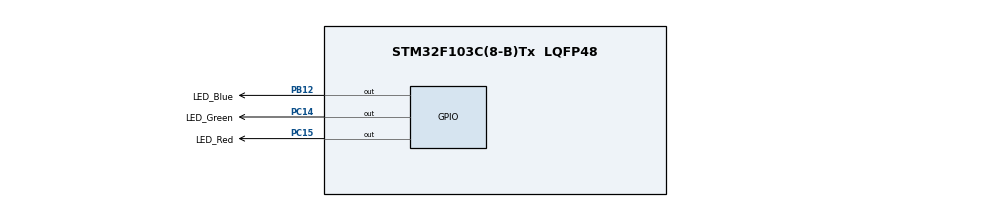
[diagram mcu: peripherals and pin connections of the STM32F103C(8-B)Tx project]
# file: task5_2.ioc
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FREERTOS.Tasks01=defaultTask,0,128,StartDefaultTask,Default,NULL,Dynamic,NULL,NULL;GreenLedTask,-1,128,StartGreenLedTask,Default,NULL,Dynamic,NULL,NULL;RedLedTask,0,128,StartRedLedTask,Default,NULL,Dynamic,NULL,NULL
Mcu.Family=STM32F1
Mcu.Name=STM32F103C(8-B)Tx
Mcu.Package=LQFP48
NVIC.PriorityGroup=NVIC_PRIORITYGROUP_4
NVIC.TIM2_IRQn=true\:15\:0\:false\:false\:true\:false\:false\:true\:true
NVIC.TimeBase=TIM2_IRQn
NVIC.TimeBaseIP=TIM2
PA13.Mode=Serial_Wire
PA13.Signal=SYS_JTMS-SWDIO
PA14.Mode=Serial_Wire
PA14.Signal=SYS_JTCK-SWCLK
PB12.GPIO_Label=LED_Blue
PB12.Signal=GPIO_Output
PC14-OSC32_IN.GPIO_Label=LED_Green
PC14-OSC32_IN.Signal=GPIO_Output
PC15-OSC32_OUT.GPIO_Label=LED_Red
PC15-OSC32_OUT.Signal=GPIO_Output
PD0-OSC_IN.Mode=HSE-External-Oscillator
PD0-OSC_IN.Signal=RCC_OSC_IN
PD1-OSC_OUT.Mode=HSE-External-Oscillator
PD1-OSC_OUT.Signal=RCC_OSC_OUT
ProjectManager.HeapSize=0x200
ProjectManager.StackSize=0x400
ProjectManager.TargetToolchain=STM32CubeIDE
RCC.APB1Freq_Value=8000000
RCC.APB2Freq_Value=8000000
VP_FREERTOS_VS_CMSIS_V1.Mode=CMSIS_V1
VP_SYS_VS_tim2.Mode=TIM2
board=custom

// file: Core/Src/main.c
/* USER CODE BEGIN Header */
/**
  ******************************************************************************
  * @file           : main.c
  * @brief          : Main program body
  ******************************************************************************
  * @attention
  *
  * Copyright (c) 2024 STMicroelectronics.
  * All rights reserved.
  *
  * This software is licensed under terms that can be found in the LICENSE file
  * in the root directory of this software component.
  * If no LICENSE file comes with this software, it is provided AS-IS.
  *
  ******************************************************************************
  */
/* USER CODE END Header */
#include "main.h"
#include "cmsis_os.h"

/* USER CODE BEGIN PD */
#define DELAY_GREEN 500    // Delay untuk LED Hijau (500 ms)
#define DELAY_RED 100      // Delay untuk LED Merah (100 ms)
#define DELAY_SHARED 500   // Delay untuk Akses Shared Data (500 ms)

/* USER CODE END PD */

osThreadId defaultTaskHandle;
osThreadId GreenLedTaskHandle;
osThreadId RedLedTaskHandle;
/* USER CODE BEGIN PV */
volatile int FlagGreen = 0;  // Flag untuk status Green LED (PA1)
volatile int FlagRed = 0;    // Flag untuk status Red LED (PA2)
volatile int FlagBlue = 0;   // Flag untuk status Blue LED (PA3)
/* USER CODE END PV */

void SystemClock_Config(void);
static void MX_GPIO_Init(void);
void StartDefaultTask(void const * argument);
void StartGreenLedTask(void const * argument);
void StartRedLedTask(void const * argument);

int main(void)
{

  /* MCU Configuration--------------------------------------------------------*/

  /* Reset of all peripherals, Initializes the Flash interface and the Systick. */
  HAL_Init();

  /* Configure the system clock */
  SystemClock_Config();

  /* Initialize all configured peripherals */
  MX_GPIO_Init();

  /* Create the thread(s) */
  /* definition and creation of defaultTask */
  osThreadDef(defaultTask, StartDefaultTask, osPriorityNormal, 0, 128);
  defaultTaskHandle = osThreadCreate(osThread(defaultTask), NULL);

  /* definition and creation of GreenLedTask */
  osThreadDef(GreenLedTask, StartGreenLedTask, osPriorityBelowNormal, 0, 128);
  GreenLedTaskHandle = osThreadCreate(osThread(GreenLedTask), NULL);

  /* definition and creation of RedLedTask */
  osThreadDef(RedLedTask, StartRedLedTask, osPriorityNormal, 0, 128);
  RedLedTaskHandle = osThreadCreate(osThread(RedLedTask), NULL);

  /* Start scheduler */
  osKernelStart();

  /* We should never get here as control is now taken by the scheduler */

  /* Infinite loop */
  while (1)
  {

  }
}

void SystemClock_Config(void)
{
  RCC_OscInitTypeDef RCC_OscInitStruct = {0};
  RCC_ClkInitTypeDef RCC_ClkInitStruct = {0};

  /** Initializes the RCC Oscillators according to the specified parameters
  * in the RCC_OscInitTypeDef structure.
  */
  RCC_OscInitStruct.OscillatorType = RCC_OSCILLATORTYPE_HSI;
  RCC_OscInitStruct.HSIState = RCC_HSI_ON;
  RCC_OscInitStruct.HSICalibrationValue = RCC_HSICALIBRATION_DEFAULT;
  RCC_OscInitStruct.PLL.PLLState = RCC_PLL_NONE;
  if (HAL_RCC_OscConfig(&RCC_OscInitStruct) != HAL_OK)
  {
    Error_Handler();
  }

  /** Initializes the CPU, AHB and APB buses clocks
  */
  RCC_ClkInitStruct.ClockType = RCC_CLOCKTYPE_HCLK|RCC_CLOCKTYPE_SYSCLK
                              |RCC_CLOCKTYPE_PCLK1|RCC_CLOCKTYPE_PCLK2;
  RCC_ClkInitStruct.SYSCLKSource = RCC_SYSCLKSOURCE_HSI;
  RCC_ClkInitStruct.AHBCLKDivider = RCC_SYSCLK_DIV1;
  RCC_ClkInitStruct.APB1CLKDivider = RCC_HCLK_DIV1;
  RCC_ClkInitStruct.APB2CLKDivider = RCC_HCLK_DIV1;

  if (HAL_RCC_ClockConfig(&RCC_ClkInitStruct, FLASH_LATENCY_0) != HAL_OK)
  {
    Error_Handler();
  }
}

static void MX_GPIO_Init(void)
{
  GPIO_InitTypeDef GPIO_InitStruct = {0};

  /* GPIO Ports Clock Enable */
  __HAL_RCC_GPIOC_CLK_ENABLE();
  __HAL_RCC_GPIOD_CLK_ENABLE();
  __HAL_RCC_GPIOB_CLK_ENABLE();
  __HAL_RCC_GPIOA_CLK_ENABLE();

  /*Configure GPIO pin Output Level */
  HAL_GPIO_WritePin(GPIOC, LED_Green_Pin|LED_Red_Pin, GPIO_PIN_RESET);

  /*Configure GPIO pin Output Level */
  HAL_GPIO_WritePin(LED_Blue_GPIO_Port, LED_Blue_Pin, GPIO_PIN_RESET);

  /*Configure GPIO pins : LED_Green_Pin LED_Red_Pin */
  GPIO_InitStruct.Pin = LED_Green_Pin|LED_Red_Pin;
  GPIO_InitStruct.Mode = GPIO_MODE_OUTPUT_PP;
  GPIO_InitStruct.Pull = GPIO_NOPULL;
  GPIO_InitStruct.Speed = GPIO_SPEED_FREQ_LOW;
  HAL_GPIO_Init(GPIOC, &GPIO_InitStruct);

  /*Configure GPIO pin : LED_Blue_Pin */
  GPIO_InitStruct.Pin = LED_Blue_Pin;
  GPIO_InitStruct.Mode = GPIO_MODE_OUTPUT_PP;
  GPIO_InitStruct.Pull = GPIO_NOPULL;
  GPIO_InitStruct.Speed = GPIO_SPEED_FREQ_LOW;
  HAL_GPIO_Init(LED_Blue_GPIO_Port, &GPIO_InitStruct);

}

/* USER CODE BEGIN 4 */
void AccessSharedData(void)
{
  // Cek kondisi FlagGreen dan FlagRed
  if (FlagGreen == 1 && FlagRed == 1)
  {
    // PA1 (Green) dan PA2 (Red) keduanya menyala, nyalakan LED PA3 (Blue)
    if (FlagBlue == 0) {
      HAL_GPIO_WritePin(GPIOB, GPIO_PIN_12, GPIO_PIN_SET);  // Menyalakan LED PA3 (Blue)
      FlagBlue = 1;  // Set FlagBlue ke 1 untuk menunjukkan PA3 menyala
    }
  }
  else
  {
    // Salah satu atau kedua LED tidak menyala, matikan LED PA3 (Blue)
    if (FlagBlue == 1) {
      HAL_GPIO_WritePin(GPIOB, GPIO_PIN_12, GPIO_PIN_RESET);  // Mematikan LED PA3 (Blue)
      FlagBlue = 0;  // Set FlagBlue ke 0 untuk menunjukkan PA3 mati
    }
  }

  // Menunggu selama 500 ms untuk simulasi operasi read/write
  osDelay(DELAY_SHARED);
}
/* USER CODE END 4 */

void StartDefaultTask(void const * argument)
{
  for(;;)
  {
    osDelay(1);
  }
}

void StartGreenLedTask(void const * argument)
{
  /* USER CODE BEGIN StartGreenLedTask */
  /* Infinite loop */
  for(;;)
  {
    HAL_GPIO_WritePin(GPIOC, GPIO_PIN_14, GPIO_PIN_SET);  // Turn Green LED on
    FlagGreen = 1;  // Set FlagGreen to 1, Green LED is on
    AccessSharedData();   // Access the shared data
    HAL_GPIO_WritePin(GPIOC, GPIO_PIN_14, GPIO_PIN_RESET);  // Turn Green LED off
    FlagGreen = 0;  // Set FlagGreen to 0, Green LED is off
    osDelay(DELAY_GREEN);  // Delay 500 ms
  }
  /* USER CODE END StartGreenLedTask */
}

void StartRedLedTask(void const * argument)
{
  /* USER CODE BEGIN StartRedLedTask */
  /* Infinite loop */
  for(;;)
  {
    HAL_GPIO_WritePin(GPIOC, GPIO_PIN_15, GPIO_PIN_SET);  // Turn Red LED on
    FlagRed = 1;  // Set FlagRed to 1, Red LED is on
    AccessSharedData();  // Access the shared data
    HAL_GPIO_WritePin(GPIOC, GPIO_PIN_15, GPIO_PIN_RESET);  // Turn Red LED off
    FlagRed = 0;  // Set FlagRed to 0, Red LED is off
    osDelay(DELAY_RED);  // Delay 100 ms
  }
  /* USER CODE END StartRedLedTask */
}

void HAL_TIM_PeriodElapsedCallback(TIM_HandleTypeDef *htim)
{
  if (htim->Instance == TIM2) {
    HAL_IncTick();
  }
}

void Error_Handler(void)
{
  __disable_irq();
  while (1)
  {
  }
}
